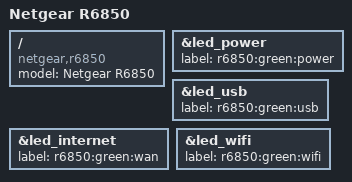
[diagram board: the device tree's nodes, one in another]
// SPDX-License-Identifier: GPL-2.0
/dts-v1/;

#include "mt7621_netgear_sercomm_chj.dtsi"

#include <dt-bindings/gpio/gpio.h>
#include <dt-bindings/input/input.h>

/ {
	compatible = "netgear,r6850", "mediatek,mt7621-soc";
	model = "Netgear R6850";
};

&led_power {
	label = "r6850:green:power";
};

&led_usb {
	label = "r6850:green:usb";
};

&led_internet {
	label = "r6850:green:wan";
};

&led_wifi {
	label = "r6850:green:wifi";
};
